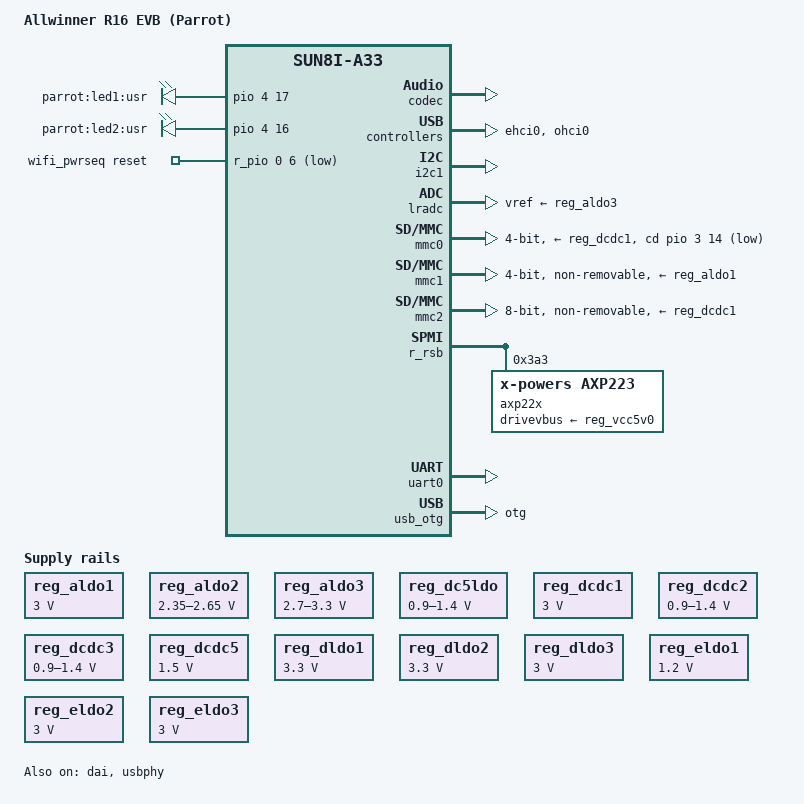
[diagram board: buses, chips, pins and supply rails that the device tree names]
/dts-v1/;
#include "sun8i-a33.dtsi"
#include "sunxi-common-regulators.dtsi"
#include <dt-bindings/gpio/gpio.h>
#include <dt-bindings/input/input.h>
/ {
	model = "Allwinner R16 EVB (Parrot)";
	compatible = "allwinner,parrot", "allwinner,sun8i-a33";
	aliases {
		serial0 = &uart0;
	};
	chosen {
		stdout-path = "serial0:115200n8";
	};
	leds {
		compatible = "gpio-leds";
		led-1 {
			label = "parrot:led1:usr";
			gpios = <&pio 4 17 GPIO_ACTIVE_HIGH>;  
		};
		led-2 {
			label = "parrot:led2:usr";
			gpios = <&pio 4 16 GPIO_ACTIVE_HIGH>;  
		};
	};
	wifi_pwrseq: wifi_pwrseq {
		compatible = "mmc-pwrseq-simple";
		reset-gpios = <&r_pio 0 6 GPIO_ACTIVE_LOW>;  
	};
};
&codec {
	status = "okay";
};
&dai {
	status = "okay";
};
&ehci0 {
	status = "okay";
};
&i2c1 {
	status = "okay";
};
&lradc {
	vref-supply = <&reg_aldo3>;
	status = "okay";
	button-190 {
		label = "V+";
		linux,code = <KEY_VOLUMEUP>;
		channel = <0>;
		voltage = <190000>;
	};
	button-390 {
		label = "V-";
		linux,code = <KEY_VOLUMEDOWN>;
		channel = <0>;
		voltage = <390000>;
	};
};
&mmc0 {
	vmmc-supply = <&reg_dcdc1>;
	cd-gpios = <&pio 3 14 GPIO_ACTIVE_LOW>;  
	bus-width = <4>;
	status = "okay";
};
&mmc1 {
	pinctrl-names = "default";
	pinctrl-0 = <&mmc1_pg_pins>;
	vmmc-supply = <&reg_aldo1>;
	mmc-pwrseq = <&wifi_pwrseq>;
	bus-width = <4>;
	non-removable;
	status = "okay";
};
&mmc2 {
	pinctrl-names = "default";
	pinctrl-0 = <&mmc2_8bit_pins>;
	vmmc-supply = <&reg_dcdc1>;
	bus-width = <8>;
	non-removable;
	cap-mmc-hw-reset;
	status = "okay";
};
&mmc2_8bit_pins {
	drive-strength = <40>;
};
&ohci0 {
	status = "okay";
};
&r_rsb {
	status = "okay";
	axp22x: pmic@3a3 {
		compatible = "x-powers,axp223";
		reg = <0x3a3>;
		interrupt-parent = <&r_intc>;
		interrupts = <GIC_SPI 32 IRQ_TYPE_LEVEL_LOW>;
		drivevbus-supply = <&reg_vcc5v0>;
		x-powers,drive-vbus-en;
	};
};
#include "axp223.dtsi"
&reg_aldo1 {
	regulator-always-on;
	regulator-min-microvolt = <3000000>;
	regulator-max-microvolt = <3000000>;
	regulator-name = "vcc-io";
};
&reg_aldo2 {
	regulator-always-on;
	regulator-min-microvolt = <2350000>;
	regulator-max-microvolt = <2650000>;
	regulator-name = "vdd-dll";
};
&reg_aldo3 {
	regulator-always-on;
	regulator-min-microvolt = <2700000>;
	regulator-max-microvolt = <3300000>;
	regulator-name = "vcc-pll-avcc";
};
&reg_dc5ldo {
	regulator-always-on;
	regulator-min-microvolt = <900000>;
	regulator-max-microvolt = <1400000>;
	regulator-name = "vdd-cpus";
};
&reg_dcdc1 {
	regulator-always-on;
	regulator-min-microvolt = <3000000>;
	regulator-max-microvolt = <3000000>;
	regulator-name = "vcc-3v0";
};
&reg_dcdc2 {
	regulator-always-on;
	regulator-min-microvolt = <900000>;
	regulator-max-microvolt = <1400000>;
	regulator-name = "vdd-sys";
};
&reg_dcdc3 {
	regulator-always-on;
	regulator-min-microvolt = <900000>;
	regulator-max-microvolt = <1400000>;
	regulator-name = "vdd-cpu";
};
&reg_dcdc5 {
	regulator-always-on;
	regulator-min-microvolt = <1500000>;
	regulator-max-microvolt = <1500000>;
	regulator-name = "vcc-dram";
};
&reg_dldo1 {
	regulator-always-on;
	regulator-min-microvolt = <3300000>;
	regulator-max-microvolt = <3300000>;
	regulator-name = "vcc-wifi0";
};
&reg_dldo2 {
	regulator-always-on;
	regulator-min-microvolt = <3300000>;
	regulator-max-microvolt = <3300000>;
	regulator-name = "vcc-wifi1";
};
&reg_dldo3 {
	regulator-min-microvolt = <3000000>;
	regulator-max-microvolt = <3000000>;
	regulator-name = "vcc-3v0-csi";
};
&reg_drivevbus {
	regulator-name = "usb0-vbus";
	status = "okay";
};
&reg_eldo1 {
	regulator-min-microvolt = <1200000>;
	regulator-max-microvolt = <1200000>;
	regulator-name = "vcc-1v2-hsic";
};
&reg_eldo2 {
	regulator-min-microvolt = <3000000>;
	regulator-max-microvolt = <3000000>;
	regulator-name = "vcc-dsp";
};
&reg_eldo3 {
	regulator-min-microvolt = <3000000>;
	regulator-max-microvolt = <3000000>;
	regulator-name = "eldo3";
};
&reg_usb1_vbus {
	gpio = <&pio 3 12 GPIO_ACTIVE_HIGH>;  
	status = "okay";
};
&sound {
	status = "okay";
};
&uart0 {
	pinctrl-names = "default";
	pinctrl-0 = <&uart0_pb_pins>;
	status = "okay";
};
&usb_otg {
	dr_mode = "otg";
	status = "okay";
};
&usb_power_supply {
	status = "okay";
};
&usbphy {
	status = "okay";
	usb0_vbus-supply = <&reg_drivevbus>;
	usb0_id_det-gpios = <&pio 3 10 (GPIO_ACTIVE_HIGH | GPIO_PULL_UP)>;  
	usb0_vbus_power-supply = <&usb_power_supply>;
	usb1_vbus-supply = <&reg_usb1_vbus>;
};
